# ATUC128L3U device description
Architecture: AVR32_UC3; Family: AVR UC3
Registers are 32-bit, read-write, reset 0x0 unless marked. A register's access mark holds for its fields unless they carry their own. Offsets are from the block's base; [hi:lo] are bit positions; {n}, {i} and the like mark numbered series.

## USBC — USB 2.0 Interface
Instances: USBC 0xfffe1000
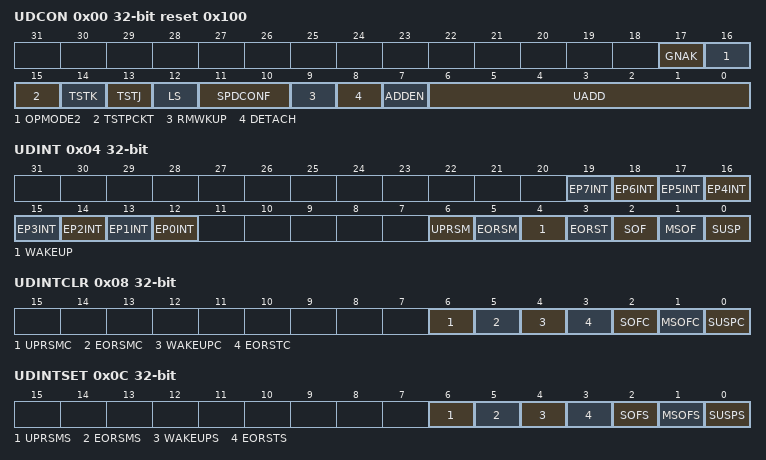
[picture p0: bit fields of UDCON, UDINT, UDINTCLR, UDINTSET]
0x00 UDCON reset 0x100 — Device General Control Register
  [17] GNAK — Global NAK
  [16] OPMODE2 — Specific Operational mode
  [15] TSTPCKT — Test Packet mode
  [14] TSTK — Test mode K
  [13] TSTJ — Test mode J
  [12] LS — Low Speed Mode Force
  [11:10] SPDCONF — Speed configuration
  [9] RMWKUP — Remote Wake-Up
  [8] DETACH
  [7] ADDEN — Address Enable
  [6:0] UADD — USB Address
0x04 UDINT ro — Device Global Interupt Register
  [n+12] EP{n}INT (n=0..7) — Endpoint {n} Interrupt
  [6] UPRSM — Upstream Resume Interrupt
  [5] EORSM — End Of Resume Interrupt
  [4] WAKEUP — Wake-Up Interrupt
  [3] EORST — End of Reset Interrupt
  [2] SOF — Start of Frame Interrupt
  [1] MSOF — Micro Start of Frame Interrupt
  [0] SUSP — Suspend Interrupt
0x08 UDINTCLR wo — Device Global Interrupt Clear Register
  [6] UPRSMC — UPRSM Interrupt Clear
  [5] EORSMC — EORSM Interrupt Clear
  [4] WAKEUPC — WAKEUP Interrupt Clear
  [3] EORSTC — EORST Interrupt Clear
  [2] SOFC — SOF Interrupt Clear
  [1] MSOFC — MSOF Interrupt Clear
  [0] SUSPC — SUSP Interrupt Clear
0x0C UDINTSET wo — Device Global Interrupt Set Regsiter
  [6] UPRSMS — UPRSM Interrupt Set
  [5] EORSMS — EORSM Interrupt Set
  [4] WAKEUPS — WAKEUP Interrupt Set
  [3] EORSTS — EORST Interrupt Set
  [2] SOFS — SOF Interrupt Set
  [1] MSOFS — MSOF Interrupt Set
  [0] SUSPS — SUSP Interrupt Set
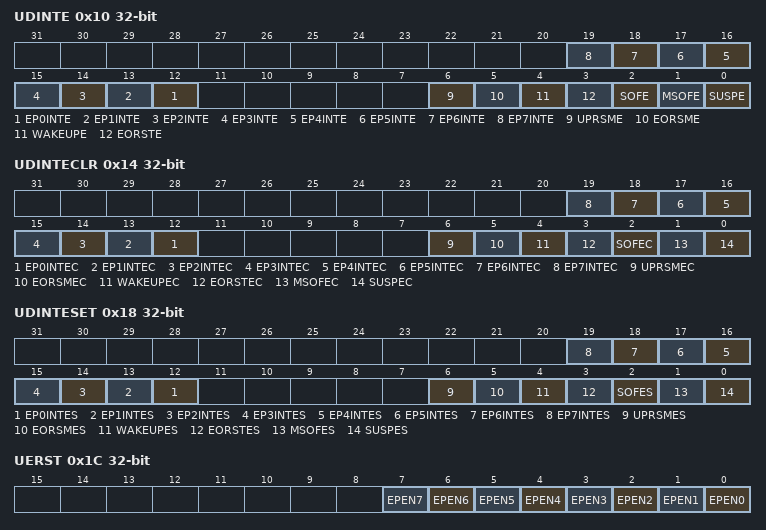
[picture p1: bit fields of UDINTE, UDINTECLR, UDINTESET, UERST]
0x10 UDINTE ro — Device Global Interrupt Enable Register
  [n+12] EP{n}INTE (n=0..7) — EP{n}INT Interrupt Enable
  [6] UPRSME — UPRSM Interrupt Enable
  [5] EORSME — EORSM Interrupt Enable
  [4] WAKEUPE — WAKEUP Interrupt Enable
  [3] EORSTE — EORST Interrupt Enable
  [2] SOFE — SOF Interrupt Enable
  [1] MSOFE — MSOF Interrupt Enable
  [0] SUSPE — SUSP Interrupt Enable
0x14 UDINTECLR wo — Device Global Interrupt Enable Clear Register
  [n+12] EP{n}INTEC (n=0..7) — EP{n}INT Interrupt Enable Clear
  [6] UPRSMEC — UPRSM Interrupt Enable Clear
  [5] EORSMEC — EORSM Interrupt Enable Clear
  [4] WAKEUPEC — WAKEUP Interrupt Enable Clear
  [3] EORSTEC — EORST Interrupt Enable Clear
  [2] SOFEC — SOF Interrupt Enable Clear
  [1] MSOFEC — MSOF Interrupt Enable Clear
  [0] SUSPEC — SUSP Interrupt Enable Clear
0x18 UDINTESET wo — Device Global Interrupt Enable Set Register
  [n+12] EP{n}INTES (n=0..7) — EP{n}INT Interrupt Enable Set
  [6] UPRSMES — UPRSM Interrupt Enable Set
  [5] EORSMES — EORSM Interrupt Enable Set
  [4] WAKEUPES — WAKEUP Interrupt Enable Set
  [3] EORSTES — EORST Interrupt Enable Set
  [2] SOFES — SOF Interrupt Enable Set
  [1] MSOFES — MSOF Interrupt Enable Set
  [0] SUSPES — SUSP Interrupt Enable Set
0x1C UERST — Endpoint Enable/Reset Register
  [n] EPEN{n} (n=0..7) — Endpoint{n} Enable
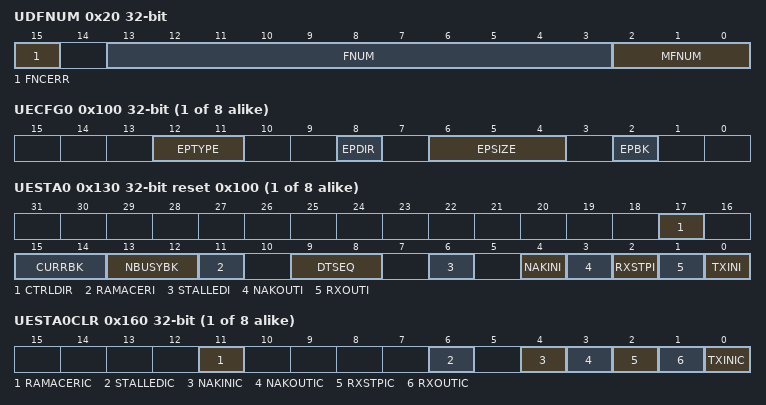
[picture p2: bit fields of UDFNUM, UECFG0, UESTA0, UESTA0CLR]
0x20 UDFNUM ro — Device Frame Number Register
  [15] FNCERR — Frame Number CRC Error
  [13:3] FNUM — Frame Number
  [2:0] MFNUM — Micro Frame Number
{0x100+4i} UECFG{i} (i=0..7) — Endpoint Configuration Register
  [12:11] EPTYPE — Endpoint Type
    0=CONTROL; 1=ISOCHRONOUS; 2=BULK; 3=INTERRUPT
  [8] EPDIR — Endpoint Direction
    0=OUT; 1=IN
  [6:4] EPSIZE — Endpoint Size
    0=8; 1=16; 2=32; 3=64; 4=128; 5=256; 6=512; 7=1024
  [2] EPBK — Endpoint Bank
    0=SINGLE; 1=DOUBLE; 2=TRIPLE
{0x130+4i} UESTA{i} ro reset 0x100 (i=0..7) — Endpoint Status Register
  [17] CTRLDIR — Control Direction
    0=OUT; 1=IN
  [15:14] CURRBK — Current Bank
  [13:12] NBUSYBK — Number Of Busy Banks
  [11] RAMACERI — Ram Access Error Interrupt
  [9:8] DTSEQ — Data Toggle Sequence
  [6] STALLEDI — STALLed Interrupt
  [4] NAKINI — NAKed IN Interrupt
  [3] NAKOUTI — NAKed OUT Interrupt
  [2] RXSTPI — Received SETUP Interrupt
  [1] RXOUTI — Received OUT Data Interrupt
  [0] TXINI — Transmitted IN Data Interrupt
{0x160+4i} UESTA{i}CLR wo (i=0..7) — Endpoint Status Clear Register
  [11] RAMACERIC — RAMACERI Clear
  [6] STALLEDIC — STALLEDI Clear
  [4] NAKINIC — NAKINI Clear
  [3] NAKOUTIC — NAKOUTI Clear
  [2] RXSTPIC — RXSTPI Clear
  [1] RXOUTIC — RXOUTI Clear
  [0] TXINIC — TXINI Clear
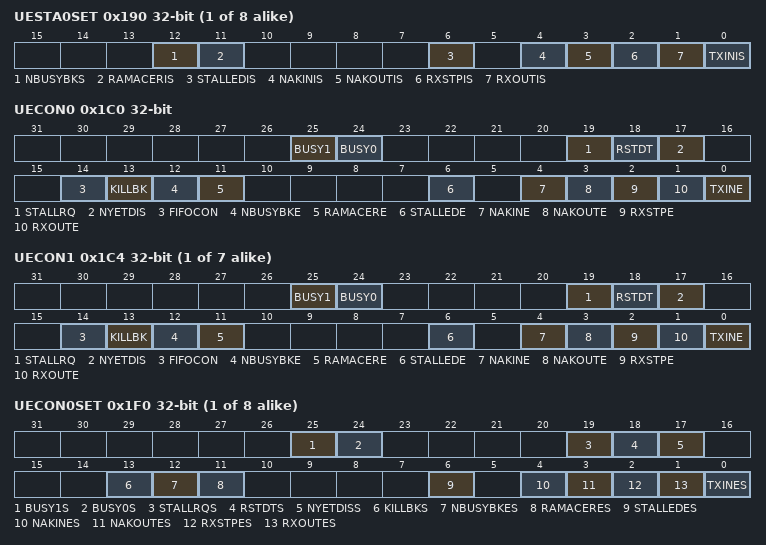
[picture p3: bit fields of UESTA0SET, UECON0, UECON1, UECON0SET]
{0x190+4i} UESTA{i}SET wo (i=0..7) — Endpoint Status Set Register
  [12] NBUSYBKS — NBUSYBK Set
  [11] RAMACERIS — RAMACERI Set
  [6] STALLEDIS — STALLEDI Set
  [4] NAKINIS — NAKINI Set
  [3] NAKOUTIS — NAKOUTI Set
  [2] RXSTPIS — RXSTPI Set
  [1] RXOUTIS — RXOUTI Set
  [0] TXINIS — TXINI Set
0x1C0 UECON0 ro — Endpoint Control Register
  [25] BUSY1 — Busy Bank0 Enable
  [24] BUSY0 — Busy Bank1 Enable
  [19] STALLRQ — STALL Request
  [18] RSTDT — Reset Data Toggle
  [17] NYETDIS — NYET token disable
  [14] FIFOCON — FIFO Control
  [13] KILLBK — Kill IN Bank
  [12] NBUSYBKE — Number of Busy Banks Interrupt Enable
  [11] RAMACERE — RAMACER Interrupt Enable
  [6] STALLEDE — STALLED Interrupt Enable
  [4] NAKINE — NAKIN Interrupt Enable
  [3] NAKOUTE — NAKOUT Interrupt Enable
  [2] RXSTPE — RXSTP Interrupt Enable
  [1] RXOUTE — RXOUT Interrupt Enable
  [0] TXINE — TXIN Interrupt Enable
{0x1C0+4i} UECON{i} ro (i=1..7) — Endpoint Control Register
  [25] BUSY1 — Busy Bank0 Enable
  [24] BUSY0 — Busy Bank1 Enable
  [19] STALLRQ — STALL Request
  [18] RSTDT — Reset Data Toggle
  [17] NYETDIS — NYET Token Enable
  [14] FIFOCON — FIFO Control
  [13] KILLBK — Kill IN Bank
  [12] NBUSYBKE — Number of Busy Banks Interrupt Enable
  [11] RAMACERE — RAMACER Interrupt Enable
  [6] STALLEDE — STALLED Interrupt Enable
  [4] NAKINE — NAKIN Interrupt Enable
  [3] NAKOUTE — NAKOUT Interrupt Enable
  [2] RXSTPE — RXSTP Interrupt Enable
  [1] RXOUTE — RXOUT Interrupt Enable
  [0] TXINE — TXIN Interrupt Enable
{0x1F0+4i} UECON{i}SET wo (i=0..7) — Endpoint Control Set Register
  [25] BUSY1S — BUSY1 Set
  [24] BUSY0S — BUSY0 Set
  [19] STALLRQS — STALLRQ Set
  [18] RSTDTS — RSTDT Set
  [17] NYETDISS — NYETDIS Set
  [13] KILLBKS — KILLBK Set
  [12] NBUSYBKES — NBUSYBKE Set
  [11] RAMACERES — RAMACERE Set
  [6] STALLEDES — STALLEDE Set
  [4] NAKINES — NAKINE Set
  [3] NAKOUTES — NAKOUTE Set
  [2] RXSTPES — RXSTPE Set
  [1] RXOUTES — RXOUTE Set
  [0] TXINES — TXINE Set
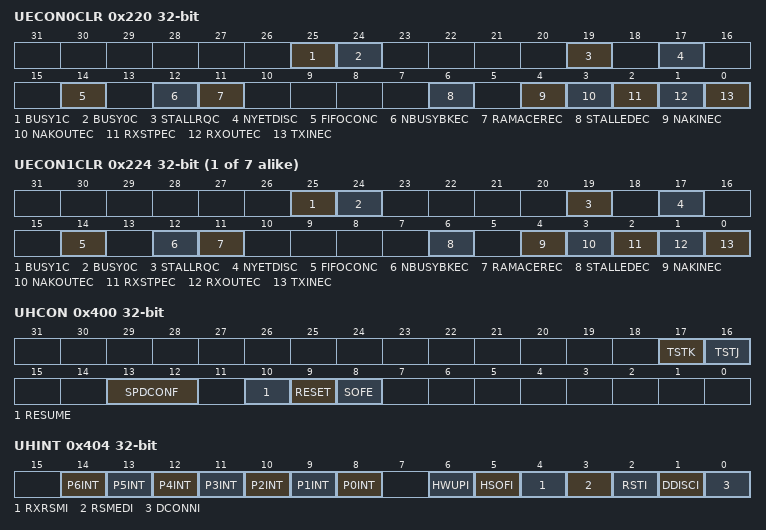
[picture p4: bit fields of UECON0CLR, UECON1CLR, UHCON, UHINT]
0x220 UECON0CLR wo — Endpoint Control Clear Register
  [25] BUSY1C — BUSY1 Clear
  [24] BUSY0C — BUSY0 Clear
  [19] STALLRQC — STALLRQ Clear
  [17] NYETDISC — NYETDIS Clear
  [14] FIFOCONC — FIFOCON Clear
  [12] NBUSYBKEC — NBUSYBKE Clear
  [11] RAMACEREC — RAMACERE Clear
  [6] STALLEDEC — STALLEDE Clear
  [4] NAKINEC — NAKINE Clear
  [3] NAKOUTEC — NAKOUTE Clear
  [2] RXSTPEC — RXSTPE Clear
  [1] RXOUTEC — RXOUTE Clear
  [0] TXINEC — TXINE Clear
{0x220+4i} UECON{i}CLR wo (i=1..7) — TXINE Clear
  [25] BUSY1C — BUSY1 Clear
  [24] BUSY0C — BUSY0 Clear
  [19] STALLRQC — STALLEDE Clear
  [17] NYETDISC — NYETDIS Clear
  [14] FIFOCONC — FIFOCON Clear
  [12] NBUSYBKEC — NBUSYBKE Clear
  [11] RAMACEREC — RAMACERE Clear
  [6] STALLEDEC — RXSTPE Clear
  [4] NAKINEC — NAKINE Clear
  [3] NAKOUTEC — NAKOUTE Clear
  [2] RXSTPEC — RXOUTE Clear
  [1] RXOUTEC — RXOUTE Clear
  [0] TXINEC — TXINE Clear
0x400 UHCON — Host General Control Register
  [17] TSTK — Test K
  [16] TSTJ — Test J
  [13:12] SPDCONF — Speed Configuration
  [10] RESUME — Send USB Resume
  [9] RESET — Send USB Reset
  [8] SOFE — SOF Enable
0x404 UHINT ro — Host Global Interrupt Register
  [n+8] P{n}INT (n=0..6) — Pipe {n} Interrupt
  [6] HWUPI — Host Wake-Up Interrupt
  [5] HSOFI — Host SOF Interrupt
  [4] RXRSMI — Upstream Resume Received Interrupt
  [3] RSMEDI — Downstream Resume Sent Interrupt
  [2] RSTI — USB Reset Sent Interrupt
  [1] DDISCI — Device Disconnection Interrupt
  [0] DCONNI — Device Connection Interrupt
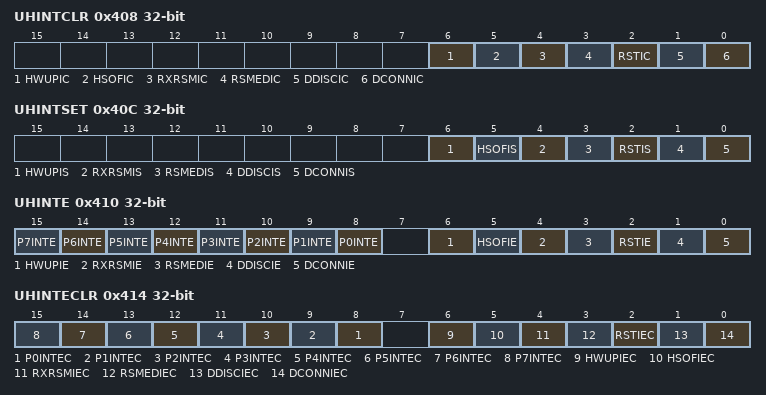
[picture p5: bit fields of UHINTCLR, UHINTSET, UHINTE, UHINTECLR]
0x408 UHINTCLR wo — Host Global Interrrupt Clear Register
  [6] HWUPIC — HWUPI Clear
  [5] HSOFIC — HSOFI Clear
  [4] RXRSMIC — RXRSMI Clear
  [3] RSMEDIC — RSMEDI Clear
  [2] RSTIC — RSTI Clear
  [1] DDISCIC — DDISCI Clear
  [0] DCONNIC — DCONNI Clear
0x40C UHINTSET wo — Host Global Interrupt Set Register
  [6] HWUPIS — HWUPI Set
  [5] HSOFIS — HSOFI Set
  [4] RXRSMIS — RXRSMI Set
  [3] RSMEDIS — RSMEDI Set
  [2] RSTIS — RSTI Set
  [1] DDISCIS — DDISCI Set
  [0] DCONNIS — DCONNI Set
0x410 UHINTE ro — Host Global Interrupt Enable Register
  [n+8] P{n}INTE (n=0..7) — P{n}INT Enable
  [6] HWUPIE — HWUPI Enable
  [5] HSOFIE — HSOFI Enable
  [4] RXRSMIE — RXRSMI Enable
  [3] RSMEDIE — RSMEDI Enable
  [2] RSTIE — RSTI Enable
  [1] DDISCIE — DDISCI Enable
  [0] DCONNIE — DCONNI Enable
0x414 UHINTECLR wo — Host Global Interrupt Enable Clear Register
  [n+8] P{n}INTEC (n=0..7) — P{n}INTE Clear
  [6] HWUPIEC — HWUPIE Clear
  [5] HSOFIEC — HSOFIE Clear
  [4] RXRSMIEC — RXRSMIE Clear
  [3] RSMEDIEC — RSMEDIE Clear
  [2] RSTIEC — RSTIE Clear
  [1] DDISCIEC — DDISCIE Clear
  [0] DCONNIEC — DCONNIE Clear
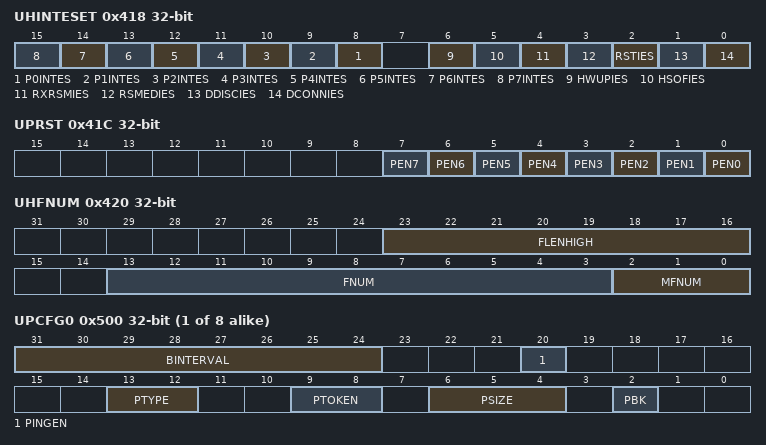
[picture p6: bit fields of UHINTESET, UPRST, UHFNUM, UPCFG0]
0x418 UHINTESET wo — Host Global Interrupt Enable Set Register
  [n+8] P{n}INTES (n=0..7) — P{n}INTE Set
  [6] HWUPIES — HWUPIE Set
  [5] HSOFIES — HSOFIE Set
  [4] RXRSMIES — RXRSMIE Set
  [3] RSMEDIES — RSMEDIE Set
  [2] RSTIES — RSTIE Set
  [1] DDISCIES — DDISCIE Set
  [0] DCONNIES — DCONNIE Set
0x41C UPRST — Pipe Reset Register
  [n] PEN{n} (n=0..7) — Pipe{n} Enable
0x420 UHFNUM — Host Frame Number Register
  [23:16] FLENHIGH — Frame Length
  [13:3] FNUM — Frame Number
  [2:0] MFNUM — Micro Frame Number
{0x500+4i} UPCFG{i} (i=0..7) — Pipe Configuration Register
  [31:24] BINTERVAL — binterval parameter
  [20] PINGEN — Ping Enable
  [13:12] PTYPE — Pipe Type
    0=CONTROL; 1=ISOCHRONOUS; 2=BULK; 3=INTERRUPT
  [9:8] PTOKEN — Pipe Token
    0=SETUP; 1=IN; 2=OUT
  [6:4] PSIZE — Pipe Size
    0=8; 1=16; 2=32; 3=64; 4=128; 5=256; 6=512; 7=1024
  [2] PBK — Pipe Banks
    0=SINGLE; 1=DOUBLE
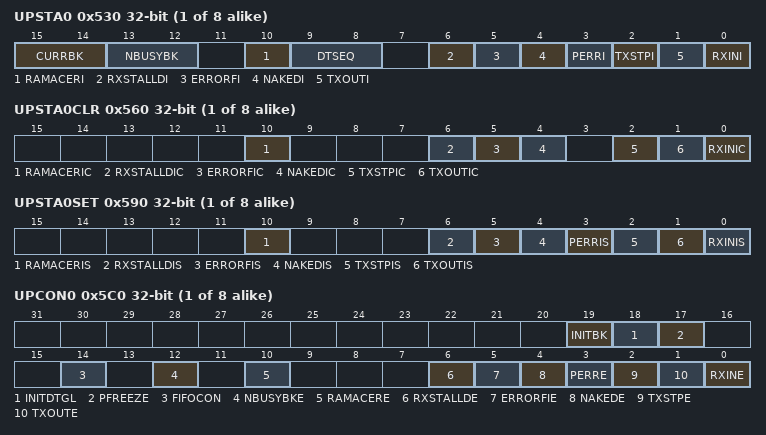
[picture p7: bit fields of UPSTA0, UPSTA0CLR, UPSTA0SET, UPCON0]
{0x530+4i} UPSTA{i} ro (i=0..7) — Pipe Status Register
  [15:14] CURRBK — Current Bank
  [13:12] NBUSYBK — Number of Busy Bank
  [10] RAMACERI — Ram Access Error Interrupt
  [9:8] DTSEQ — Data Toggle Sequence
  [6] RXSTALLDI — Received STALLed Interrupt
  [5] ERRORFI — Errorflow Interrupt
  [4] NAKEDI — NAKed Interrupt
  [3] PERRI — Pipe Error Interrupt
  [2] TXSTPI — Transmitted SETUP Interrupt
  [1] TXOUTI — Transmitted OUT Data Interrupt
  [0] RXINI — Received IN Data Interrupt
{0x560+4i} UPSTA{i}CLR wo (i=0..7) — Pipe Status Clear Register
  [10] RAMACERIC — RAMACERI Clear
  [6] RXSTALLDIC — RXSTALLDI Clear
  [5] ERRORFIC — ERRORFI Clear
  [4] NAKEDIC — NAKEDI Clear
  [2] TXSTPIC — TXSTPI Clear
  [1] TXOUTIC — TXOUTI Clear
  [0] RXINIC — RXINI Clear
{0x590+4i} UPSTA{i}SET wo (i=0..7) — Pipe Status Set Register
  [10] RAMACERIS — RAMACERI Set
  [6] RXSTALLDIS — RXSTALLDI Set
  [5] ERRORFIS — ERRORFI Set
  [4] NAKEDIS — NAKEDI Set
  [3] PERRIS — PERRI Set
  [2] TXSTPIS — TXSTPI Set
  [1] TXOUTIS — TXOUTI Set
  [0] RXINIS — RXINI Set
{0x5C0+4i} UPCON{i} ro (i=0..7) — Pipe Control Register
  [19] INITBK — Bank Initialization
  [18] INITDTGL — Data Toggle Initialization
  [17] PFREEZE — Pipe Freeze
  [14] FIFOCON — FIFO Control
  [12] NBUSYBKE — NBUSYBKInterrupt Enable
  [10] RAMACERE — RAMACER Interrupt Enable
  [6] RXSTALLDE — RXTALLD Interrupt Enable
  [5] ERRORFIE — ERRORFI Interrupt Enable
  [4] NAKEDE — NAKED Interrupt Enable
  [3] PERRE — PERR Interrupt Enable
  [2] TXSTPE — TXSTP Interrupt Enable
  [1] TXOUTE — TXOUT Interrupt Enable
  [0] RXINE — RXIN Interrupt Enable
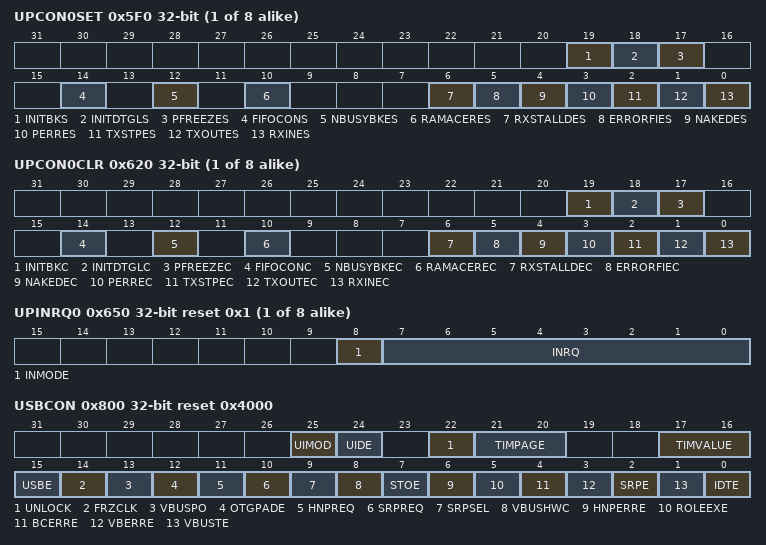
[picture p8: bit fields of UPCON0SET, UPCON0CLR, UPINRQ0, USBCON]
{0x5F0+4i} UPCON{i}SET wo (i=0..7) — Pipe Control Set Register
  [19] INITBKS — INITBK Set
  [18] INITDTGLS — INITDTGL Set
  [17] PFREEZES — PFREEZE Set
  [14] FIFOCONS — FIFOCON Set
  [12] NBUSYBKES — NBUSYBKE Set
  [10] RAMACERES — RAMACERE Set
  [6] RXSTALLDES — RXSTALLDE Set
  [5] ERRORFIES — ERRORFIE Set
  [4] NAKEDES — NAKEDE Set
  [3] PERRES — PERRE Set
  [2] TXSTPES — TXSTPE Set
  [1] TXOUTES — TXOUTE Set
  [0] RXINES — RXINE Set
{0x620+4i} UPCON{i}CLR wo (i=0..7) — Pipe Control Clear Register
  [19] INITBKC — INITBK Clear
  [18] INITDTGLC — INITDTGL Clear
  [17] PFREEZEC — PFREEZE Clear
  [14] FIFOCONC — FIFOCON Clear
  [12] NBUSYBKEC — NBUSYBKE Clear
  [10] RAMACEREC — RAMACERE Clear
  [6] RXSTALLDEC — RXTALLDE Clear
  [5] ERRORFIEC — ERRORFIE Clear
  [4] NAKEDEC — NAKEDE Clear
  [3] PERREC — PERRE Clear
  [2] TXSTPEC — TXSTPE Clear
  [1] TXOUTEC — TXOUTE Clear
  [0] RXINEC — RXINE Clear
{0x650+4i} UPINRQ{i} reset 0x1 (i=0..7) — Pipe In Request
  [8] INMODE — IN Request Mode
  [7:0] INRQ — IN Request Number before Freeze
0x800 USBCON reset 0x4000 — General Control Register
  [25] UIMOD — USBC Mode
  [24] UIDE — USB_Id Pin Enable
  [22] UNLOCK — Timer Access Unlock
  [21:20] TIMPAGE — Timer Page
    0=A_WAIT_VRISE; 1=VB_BUS_PULSING; 2=PD_TMOUT_CNT; 3=SRP_DET_TMOUT
  [17:16] TIMVALUE — Timer Value
  [15] USBE — USBC Enable
  [14] FRZCLK — Freeze USB Clock
  [13] VBUSPO — VBus Polarity
  [12] OTGPADE — OTG Pad Enable
  [11] HNPREQ — HNP Request
  [10] SRPREQ — SRP Request
  [9] SRPSEL — SRP Slection
  [8] VBUSHWC — VBUS Hardware Control
  [7] STOE — STO Interrupt Enable
  [6] HNPERRE — HNPERR Interrupt Enable
  [5] ROLEEXE — ROLEEX Interrupt Enable
  [4] BCERRE — BCERR Interrupt Enable
  [3] VBERRE — VBERR Interrupt Enable
  [2] SRPE — SRPE Interrupt Enable
  [1] VBUSTE — VBUST Interrupt Enable
  [0] IDTE — IDT Interrupt Enable
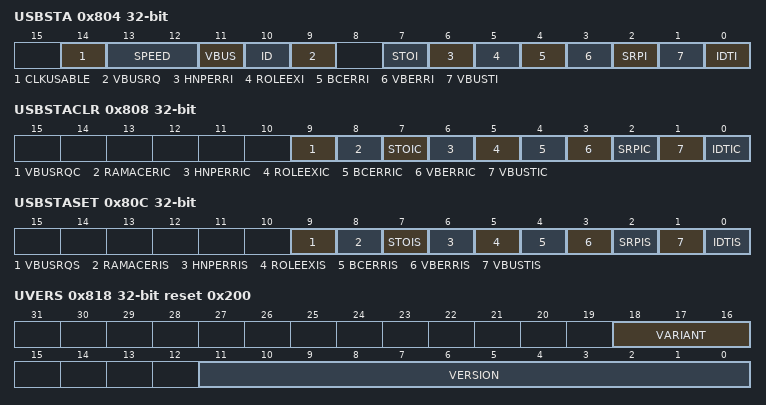
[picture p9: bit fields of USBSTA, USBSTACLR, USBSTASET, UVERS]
0x804 USBSTA ro — General Status Register
  [14] CLKUSABLE — USB Clock Usable
  [13:12] SPEED — Speed Status
    0=FULL; 1=HIGH; 2=LOW
  [11] VBUS — VBus Level
  [10] ID — USB_ID Pin State
  [9] VBUSRQ — VBus Request
  [7] STOI — Suspend Time-Out Interrupt
  [6] HNPERRI — HNP Error Interrupt
  [5] ROLEEXI — Role Exchange Interrupt
  [4] BCERRI — B-Connection Error Interrupt
  [3] VBERRI — VBus Error Interrupt
  [2] SRPI — SRP Interrupt
  [1] VBUSTI — VBus Transition Interrupt
  [0] IDTI — ID Transition Interrupt
0x808 USBSTACLR wo — General Status Clear Register
  [9] VBUSRQC — VBUSRQ Clear
  [8] RAMACERIC — RAMACERI Clear
  [7] STOIC — STOI Clear
  [6] HNPERRIC — HNPERRI Clear
  [5] ROLEEXIC — ROLEEXI Clear
  [4] BCERRIC — BCERRI Clear
  [3] VBERRIC — VBERRI Clear
  [2] SRPIC — SRPI Clear
  [1] VBUSTIC — VBUSTI Clear
  [0] IDTIC — IDTI Clear
0x80C USBSTASET wo — General Status Set Register
  [9] VBUSRQS — VBUSRQ Set
  [8] RAMACERIS — RAMACERI Set
  [7] STOIS — STOI Set
  [6] HNPERRIS — HNPERRI Set
  [5] ROLEEXIS — ROLEEXI Set
  [4] BCERRIS — BCERRI Set
  [3] VBERRIS — VBERRI Set
  [2] SRPIS — SRPI Set
  [1] VBUSTIS — VBUSTI Set
  [0] IDTIS — IDTI Set
0x818 UVERS ro reset 0x200 — IP Version Register
  [18:16] VARIANT — Variant Number
  [11:0] VERSION — Version Number
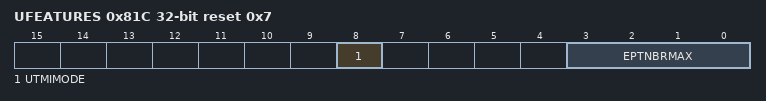
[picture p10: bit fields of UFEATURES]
0x81C UFEATURES ro reset 0x7 — IP Features Register
  [8] UTMIMODE
  [3:0] EPTNBRMAX — Maximum Number of Pipes/Endpints
0x820 UADDRSIZE ro reset 0x1000 — IP PB address size Register
  [31:0] UADDRSIZE — IP PB Address Size
0x824 UNAME1 ro reset 0x48555342 — IP name HUSB
  [31:0] UNAME1 — IP Name Part One
0x828 UNAME2 ro — IP name, 0 if Devicel only, else OTG
  [31:0] UNAME2 — IP Name Part Two
0x82C USBFSM ro reset 0x9 — USB internal finite state machine
  [3:0] DRDSTATE — DualRoleDevice state
    0=A_IDLE; 1=A_WAIT_VRISE; 2=A_WAIT_BCON; 3=A_HOST; 4=A_SUSPEND; 5=A_PERIPHERAL; 6=A_WAIT_VFALL; 7=A_VBUS_ERR; 8=A_WAIT_DISCHARGE; 9=B_IDLE; 10=B_PERIPHERAL; 11=B_WAIT_BEGIN_HNP; 12=B_WAIT_DISCHARGE; 13=B_WAIT_ACON; 14=B_HOST; 15=B_SRP_INIT
0x830 UDESC — Endpoint descriptor table
  [31:0] UDESCA — USB Descriptor Address
